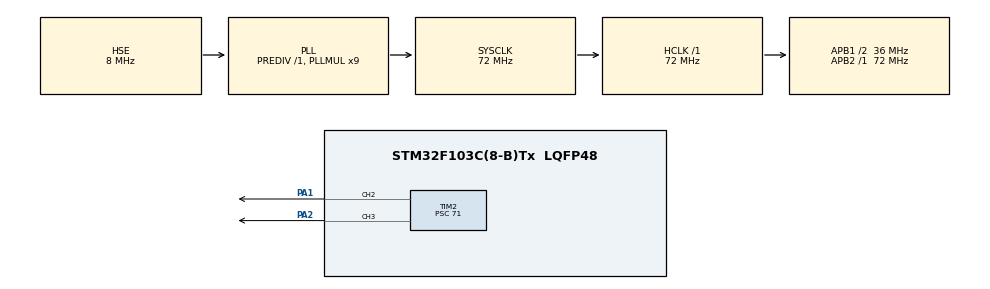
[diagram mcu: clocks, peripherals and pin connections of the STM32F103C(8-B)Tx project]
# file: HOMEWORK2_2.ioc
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Mcu.Family=STM32F1
Mcu.Name=STM32F103C(8-B)Tx
Mcu.Package=LQFP48
NVIC.PriorityGroup=NVIC_PRIORITYGROUP_4
PA1.Signal=S_TIM2_CH2
PA13.Mode=Serial_Wire
PA13.Signal=SYS_JTMS-SWDIO
PA14.Mode=Serial_Wire
PA14.Signal=SYS_JTCK-SWCLK
PA2.Signal=S_TIM2_CH3
PD0-OSC_IN.Mode=HSE-External-Oscillator
PD0-OSC_IN.Signal=RCC_OSC_IN
PD1-OSC_OUT.Mode=HSE-External-Oscillator
PD1-OSC_OUT.Signal=RCC_OSC_OUT
ProjectManager.HeapSize=0x200
ProjectManager.StackSize=0x400
ProjectManager.TargetToolchain=MDK-ARM V5.32
RCC.AHBFreq_Value=72000000
RCC.APB1CLKDivider=RCC_HCLK_DIV2
RCC.APB1Freq_Value=36000000
RCC.APB1TimFreq_Value=72000000
RCC.APB2Freq_Value=72000000
RCC.APB2TimFreq_Value=72000000
RCC.HCLKFreq_Value=72000000
RCC.PLLMUL=RCC_PLL_MUL9
RCC.PLLSourceVirtual=RCC_PLLSOURCE_HSE
RCC.SYSCLKFreq_VALUE=72000000
RCC.SYSCLKSource=RCC_SYSCLKSOURCE_PLLCLK
RCC.USBFreq_Value=72000000
SH.S_TIM2_CH2.0=TIM2_CH2,PWM Generation2 CH2
SH.S_TIM2_CH3.0=TIM2_CH3,PWM Generation3 CH3
TIM2.Channel-PWM\ Generation2\ CH2=TIM_CHANNEL_2
TIM2.Channel-PWM\ Generation3\ CH3=TIM_CHANNEL_3
TIM2.Period=19999
TIM2.Prescaler=71
TIM2.Pulse-PWM\ Generation3\ CH3=1500
board=custom

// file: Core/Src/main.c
/* USER CODE BEGIN Header */
/**
  ******************************************************************************
  * @file           : main.c
  * @brief          : Main program body
  ******************************************************************************
  * @attention
  *
  * Copyright (c) 2026 STMicroelectronics.
  * All rights reserved.
  *
  * This software is licensed under terms that can be found in the LICENSE file
  * in the root directory of this software component.
  * If no LICENSE file comes with this software, it is provided AS-IS.
  *
  ******************************************************************************
  */
/* USER CODE END Header */
#include "main.h"

TIM_HandleTypeDef htim2;

void SystemClock_Config(void);
static void MX_GPIO_Init(void);
static void MX_TIM2_Init(void);

/* USER CODE BEGIN 0 */
uint32_t curent_light = 0;//当前灯的亮度
uint32_t light_direction = 0;//灯的亮度变化量
uint32_t last_light_time = 0;//灯的上次亮度变化时间
uint32_t crr_first=500;//初始角度
uint32_t duoji_direction=1;//舵机的方向
uint32_t last_duoji_time=0;//舵机的上次转动时间
/* USER CODE END 0 */

int main(void)
{

  /* MCU Configuration--------------------------------------------------------*/

  /* Reset of all peripherals, Initializes the Flash interface and the Systick. */
  HAL_Init();

  /* Configure the system clock */
  SystemClock_Config();

  /* Initialize all configured peripherals */
  MX_GPIO_Init();
  MX_TIM2_Init();
  /* USER CODE BEGIN 2 */
HAL_TIM_PWM_Start(&htim2, TIM_CHANNEL_2);//启动定时器2的通道2
HAL_TIM_PWM_Start(&htim2, TIM_CHANNEL_3);//启动定时器2的通道3

__HAL_TIM_SET_COMPARE(&htim2, TIM_CHANNEL_2, 0);//设置灯的亮度
__HAL_TIM_SET_COMPARE(&htim2, TIM_CHANNEL_3, crr_first);//设置舵机的初始角度
  /* USER CODE END 2 */

  /* Infinite loop */
  while (1)
  {

    /* USER CODE BEGIN 3 */
    if (HAL_GetTick() - last_light_time >= 1)//每1ms改变一次灯的亮度
    {
      last_light_time = HAL_GetTick();//记录上次改变灯的时间
      curent_light += light_direction*20;//改变灯的亮度
      if (curent_light >= 20000)//当灯的亮度大于等于20000时，改变方向
      {
        light_direction = -1;
        curent_light = 20000;//防止灯的亮度大于20000
      }
      else if (curent_light <= 0)//当灯的亮度小于等于0时，改变方向
      {
        light_direction = 1;
        curent_light = 0;//防止灯的亮度小于0
      }
      __HAL_TIM_SET_COMPARE(&htim2, TIM_CHANNEL_2, curent_light);//设置灯的亮度
    }
    //以上是呼吸灯控制//以下是舵机控制
    if (HAL_GetTick() - last_duoji_time >= 20)//每20ms改变一次舵机的角度
    {
      last_duoji_time = HAL_GetTick();//记录上次改变舵机的时间
      crr_first += duoji_direction*10;//改变舵机的角度
      if (crr_first >= 2500)//当舵机的角度大于等于2500时，改变方向
      {
        duoji_direction = -1;
        crr_first = 2500;//防止舵机的角度大于2500
      }
      else if (crr_first <= 500)//当舵机的角度小于等于500时，改变方向
      {
        duoji_direction = 1;
        crr_first = 500;//防止舵机的角度小于500
      }
      __HAL_TIM_SET_COMPARE(&htim2, TIM_CHANNEL_3, crr_first);//设置舵机的角度
    }
  }
  /* USER CODE END 3 */
}

void SystemClock_Config(void)
{
  RCC_OscInitTypeDef RCC_OscInitStruct = {0};
  RCC_ClkInitTypeDef RCC_ClkInitStruct = {0};

  /** Initializes the RCC Oscillators according to the specified parameters
  * in the RCC_OscInitTypeDef structure.
  */
  RCC_OscInitStruct.OscillatorType = RCC_OSCILLATORTYPE_HSE;
  RCC_OscInitStruct.HSEState = RCC_HSE_ON;
  RCC_OscInitStruct.HSEPredivValue = RCC_HSE_PREDIV_DIV1;
  RCC_OscInitStruct.HSIState = RCC_HSI_ON;
  RCC_OscInitStruct.PLL.PLLState = RCC_PLL_ON;
  RCC_OscInitStruct.PLL.PLLSource = RCC_PLLSOURCE_HSE;
  RCC_OscInitStruct.PLL.PLLMUL = RCC_PLL_MUL9;
  if (HAL_RCC_OscConfig(&RCC_OscInitStruct) != HAL_OK)
  {
    Error_Handler();
  }

  /** Initializes the CPU, AHB and APB buses clocks
  */
  RCC_ClkInitStruct.ClockType = RCC_CLOCKTYPE_HCLK|RCC_CLOCKTYPE_SYSCLK
                              |RCC_CLOCKTYPE_PCLK1|RCC_CLOCKTYPE_PCLK2;
  RCC_ClkInitStruct.SYSCLKSource = RCC_SYSCLKSOURCE_PLLCLK;
  RCC_ClkInitStruct.AHBCLKDivider = RCC_SYSCLK_DIV1;
  RCC_ClkInitStruct.APB1CLKDivider = RCC_HCLK_DIV2;
  RCC_ClkInitStruct.APB2CLKDivider = RCC_HCLK_DIV1;

  if (HAL_RCC_ClockConfig(&RCC_ClkInitStruct, FLASH_LATENCY_2) != HAL_OK)
  {
    Error_Handler();
  }
}

static void MX_TIM2_Init(void)
{

  TIM_MasterConfigTypeDef sMasterConfig = {0};
  TIM_OC_InitTypeDef sConfigOC = {0};

  htim2.Instance = TIM2;
  htim2.Init.Prescaler = 71;
  htim2.Init.CounterMode = TIM_COUNTERMODE_UP;
  htim2.Init.Period = 19999;
  htim2.Init.ClockDivision = TIM_CLOCKDIVISION_DIV1;
  htim2.Init.AutoReloadPreload = TIM_AUTORELOAD_PRELOAD_DISABLE;
  if (HAL_TIM_PWM_Init(&htim2) != HAL_OK)
  {
    Error_Handler();
  }
  sMasterConfig.MasterOutputTrigger = TIM_TRGO_RESET;
  sMasterConfig.MasterSlaveMode = TIM_MASTERSLAVEMODE_DISABLE;
  if (HAL_TIMEx_MasterConfigSynchronization(&htim2, &sMasterConfig) != HAL_OK)
  {
    Error_Handler();
  }
  sConfigOC.OCMode = TIM_OCMODE_PWM1;
  sConfigOC.Pulse = 0;
  sConfigOC.OCPolarity = TIM_OCPOLARITY_HIGH;
  sConfigOC.OCFastMode = TIM_OCFAST_DISABLE;
  if (HAL_TIM_PWM_ConfigChannel(&htim2, &sConfigOC, TIM_CHANNEL_2) != HAL_OK)
  {
    Error_Handler();
  }
  sConfigOC.Pulse = 1500;
  if (HAL_TIM_PWM_ConfigChannel(&htim2, &sConfigOC, TIM_CHANNEL_3) != HAL_OK)
  {
    Error_Handler();
  }
  HAL_TIM_MspPostInit(&htim2);

}

static void MX_GPIO_Init(void)
{

  /* GPIO Ports Clock Enable */
  __HAL_RCC_GPIOD_CLK_ENABLE();
  __HAL_RCC_GPIOA_CLK_ENABLE();

}

void Error_Handler(void)
{
  __disable_irq();
  while (1)
  {
  }
}
